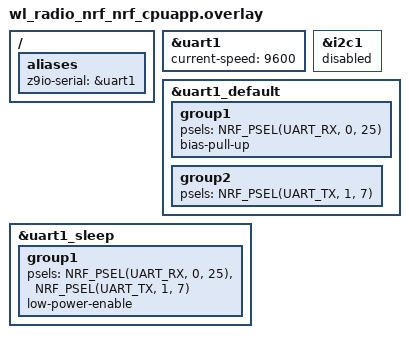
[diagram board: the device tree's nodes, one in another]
// To get started, press Ctrl+Space (or Option+Esc) to bring up the completion menu and view the available nodes.

// You can also use the buttons in the sidebar to perform actions on nodes.
// Actions currently available include:

// * Enabling / disabling the node
// * Adding the bus to a bus
// * Removing the node
// * Connecting ADC channels

// For more help, browse the DeviceTree documentation at https://docs.zephyrproject.org/latest/guides/dts/index.html
// You can also visit the nRF DeviceTree extension documentation at https://nrfconnect.github.io/vscode-nrf-connect/devicetree/nrfdevicetree.html
// set UART1 to standard Arduino PINs
/ {
aliases { z9io-serial = &uart1; };
};

&uart1 {
    current-speed = <9600>;
    status = "okay";
};

&i2c1 { status = "disabled"; };

	&uart1_default {
		group1 {
			psels = <NRF_PSEL(UART_RX, 0, 25)>;
			bias-pull-up;
		};
		group2 {
			psels = <NRF_PSEL(UART_TX, 1, 7)>;
		};
};

&uart1_sleep {
	group1 {
	psels = <NRF_PSEL(UART_RX, 0, 25)>, <NRF_PSEL(UART_TX, 1, 7)>;
	low-power-enable;
	};
};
